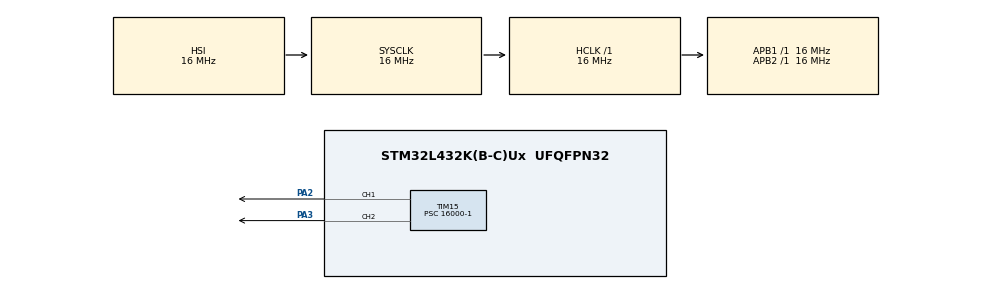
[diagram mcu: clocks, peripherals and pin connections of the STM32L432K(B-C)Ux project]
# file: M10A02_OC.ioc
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Mcu.Family=STM32L4
Mcu.Name=STM32L432K(B-C)Ux
Mcu.Package=UFQFPN32
NVIC.PriorityGroup=NVIC_PRIORITYGROUP_4
PA2.Signal=S_TIM15_CH1
PA3.Signal=S_TIM15_CH2
ProjectManager.HeapSize=0x200
ProjectManager.StackSize=0x400
ProjectManager.TargetToolchain=STM32CubeIDE
RCC.AHBFreq_Value=16000000
RCC.APB1Freq_Value=16000000
RCC.APB1TimFreq_Value=16000000
RCC.APB2Freq_Value=16000000
RCC.APB2TimFreq_Value=16000000
RCC.CortexFreq_Value=16000000
RCC.HCLKFreq_Value=16000000
RCC.HSE_VALUE=8000000
RCC.HSI16_VALUE=16000000
RCC.HSI48_VALUE=48000000
RCC.HSI_VALUE=16000000
RCC.LSE_VALUE=32768
RCC.MSI_VALUE=4000000
RCC.PLLMUL=RCC_PLLMUL_4
RCC.PLLN=16
RCC.SYSCLKFreq_VALUE=16000000
RCC.SYSCLKSource=RCC_SYSCLKSOURCE_HSI
RCC.VCOOutputFreq_Value=64000000
SH.S_TIM15_CH1.0=TIM15_CH1,Output Compare1 CH1
SH.S_TIM15_CH2.0=TIM15_CH2,Output Compare2 CH2
TIM15.Channel-Output\ Compare1\ CH1=TIM_CHANNEL_1
TIM15.Channel-Output\ Compare2\ CH2=TIM_CHANNEL_2
TIM15.OCMode_1=TIM_OCMODE_TOGGLE
TIM15.OCMode_2=TIM_OCMODE_TOGGLE
TIM15.Period=1000-1
TIM15.Prescaler=16000-1
TIM15.Pulse-Output\ Compare2\ CH2=500
VP_TIM15_VS_ClockSourceINT.Mode=Internal
board=NUCLEO-L432KC

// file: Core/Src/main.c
/* USER CODE BEGIN Header */
/**
  ******************************************************************************
  * @file           : main.c
  * @brief          : Main program body
  ******************************************************************************
  * @attention
  *
  * Copyright (c) 2023 STMicroelectronics.
  * All rights reserved.
  *
  * This software is licensed under terms that can be found in the LICENSE file
  * in the root directory of this software component.
  * If no LICENSE file comes with this software, it is provided AS-IS.
  *
  ******************************************************************************
  */
/* USER CODE END Header */
#include "main.h"
#include "tim.h"
#include "gpio.h"

void SystemClock_Config(void);

int main(void)
{

  /* MCU Configuration--------------------------------------------------------*/

  /* Reset of all peripherals, Initializes the Flash interface and the Systick. */
  HAL_Init();

  /* Configure the system clock */
  SystemClock_Config();

  /* Initialize all configured peripherals */
  MX_GPIO_Init();
  MX_TIM15_Init();
  /* USER CODE BEGIN 2 */
  HAL_TIM_OC_Start(&htim15, TIM_CHANNEL_1);
  HAL_TIM_OC_Start(&htim15, TIM_CHANNEL_2);
  /* USER CODE END 2 */

  /* Infinite loop */
  while (1)
  {

  }
}

void SystemClock_Config(void)
{
  RCC_OscInitTypeDef RCC_OscInitStruct = {0};
  RCC_ClkInitTypeDef RCC_ClkInitStruct = {0};

  /** Configure the main internal regulator output voltage
  */
  if (HAL_PWREx_ControlVoltageScaling(PWR_REGULATOR_VOLTAGE_SCALE1) != HAL_OK)
  {
    Error_Handler();
  }

  /** Initializes the RCC Oscillators according to the specified parameters
  * in the RCC_OscInitTypeDef structure.
  */
  RCC_OscInitStruct.OscillatorType = RCC_OSCILLATORTYPE_HSI;
  RCC_OscInitStruct.HSIState = RCC_HSI_ON;
  RCC_OscInitStruct.HSICalibrationValue = RCC_HSICALIBRATION_DEFAULT;
  RCC_OscInitStruct.PLL.PLLState = RCC_PLL_NONE;
  if (HAL_RCC_OscConfig(&RCC_OscInitStruct) != HAL_OK)
  {
    Error_Handler();
  }

  /** Initializes the CPU, AHB and APB buses clocks
  */
  RCC_ClkInitStruct.ClockType = RCC_CLOCKTYPE_HCLK|RCC_CLOCKTYPE_SYSCLK
                              |RCC_CLOCKTYPE_PCLK1|RCC_CLOCKTYPE_PCLK2;
  RCC_ClkInitStruct.SYSCLKSource = RCC_SYSCLKSOURCE_HSI;
  RCC_ClkInitStruct.AHBCLKDivider = RCC_SYSCLK_DIV1;
  RCC_ClkInitStruct.APB1CLKDivider = RCC_HCLK_DIV1;
  RCC_ClkInitStruct.APB2CLKDivider = RCC_HCLK_DIV1;

  if (HAL_RCC_ClockConfig(&RCC_ClkInitStruct, FLASH_LATENCY_0) != HAL_OK)
  {
    Error_Handler();
  }
}

void Error_Handler(void)
{
  __disable_irq();
  while (1)
  {
  }
}
